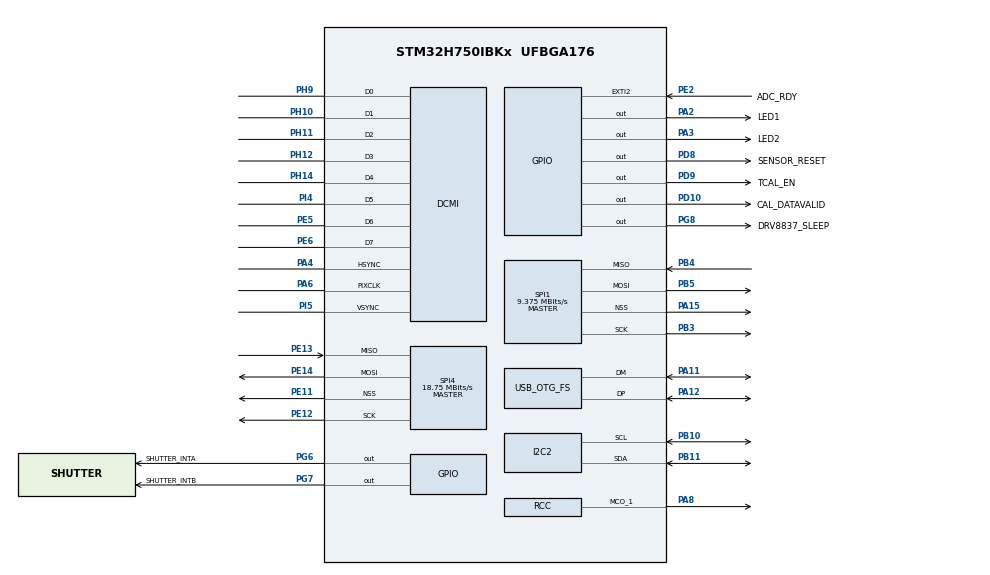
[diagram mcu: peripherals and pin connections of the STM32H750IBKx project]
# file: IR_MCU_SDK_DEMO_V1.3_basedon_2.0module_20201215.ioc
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Dma.DCMI.0.Direction=DMA_PERIPH_TO_MEMORY
Dma.DCMI.0.EventEnable=DISABLE
Dma.DCMI.0.FIFOMode=DMA_FIFOMODE_DISABLE
Dma.DCMI.0.Instance=DMA1_Stream0
Dma.DCMI.0.MemDataAlignment=DMA_MDATAALIGN_WORD
Dma.DCMI.0.MemInc=DMA_MINC_ENABLE
Dma.DCMI.0.Mode=DMA_CIRCULAR
Dma.DCMI.0.PeriphDataAlignment=DMA_PDATAALIGN_WORD
Dma.DCMI.0.PeriphInc=DMA_PINC_DISABLE
Dma.DCMI.0.Polarity=HAL_DMAMUX_REQ_GEN_RISING
Dma.DCMI.0.Priority=DMA_PRIORITY_MEDIUM
Dma.DCMI.0.RequestNumber=1
Dma.DCMI.0.SignalID=NONE
Dma.DCMI.0.SyncEnable=DISABLE
Dma.DCMI.0.SyncPolarity=HAL_DMAMUX_SYNC_NO_EVENT
Dma.DCMI.0.SyncRequestNumber=1
Dma.DCMI.0.SyncSignalID=NONE
Dma.MEMTOMEM.1.Direction=DMA_MEMORY_TO_MEMORY
Dma.MEMTOMEM.1.EventEnable=DISABLE
Dma.MEMTOMEM.1.FIFOMode=DMA_FIFOMODE_ENABLE
Dma.MEMTOMEM.1.FIFOThreshold=DMA_FIFO_THRESHOLD_FULL
Dma.MEMTOMEM.1.Instance=DMA1_Stream1
Dma.MEMTOMEM.1.MemBurst=DMA_MBURST_SINGLE
Dma.MEMTOMEM.1.MemDataAlignment=DMA_MDATAALIGN_WORD
Dma.MEMTOMEM.1.MemInc=DMA_MINC_ENABLE
Dma.MEMTOMEM.1.Mode=DMA_NORMAL
Dma.MEMTOMEM.1.PeriphBurst=DMA_PBURST_SINGLE
Dma.MEMTOMEM.1.PeriphDataAlignment=DMA_PDATAALIGN_WORD
Dma.MEMTOMEM.1.PeriphInc=DMA_PINC_ENABLE
Dma.MEMTOMEM.1.Polarity=HAL_DMAMUX_REQ_GEN_RISING
Dma.MEMTOMEM.1.Priority=DMA_PRIORITY_LOW
Dma.MEMTOMEM.1.RequestNumber=1
Dma.MEMTOMEM.1.SignalID=NONE
Dma.MEMTOMEM.1.SyncEnable=DISABLE
Dma.MEMTOMEM.1.SyncPolarity=HAL_DMAMUX_SYNC_NO_EVENT
Dma.MEMTOMEM.1.SyncRequestNumber=1
Dma.MEMTOMEM.1.SyncSignalID=NONE
Dma.Request0=DCMI
Dma.Request1=MEMTOMEM
FREERTOS.Tasks01=defaultTask,0,128,StartDefaultTask,As weak,NULL,Dynamic,NULL,NULL;irCameraTask,2,128,StartIRCameraTask,As weak,NULL,Dynamic,NULL,NULL
FREERTOS.configUSE_NEWLIB_REENTRANT=1
I2C2.Timing=0x00909FCE
Mcu.Family=STM32H7
Mcu.Name=STM32H750IBKx
Mcu.Package=UFBGA176
NVIC.DCMI_IRQn=true\:5\:0\:false\:false\:true\:true\:true\:true\:true
NVIC.DMA1_Stream0_IRQn=true\:5\:0\:false\:false\:true\:true\:false\:true\:true
NVIC.EXTI2_IRQn=true\:5\:0\:false\:false\:true\:true\:true\:true\:true
NVIC.OTG_FS_IRQn=true\:5\:0\:false\:false\:true\:true\:true\:true\:true
NVIC.PriorityGroup=NVIC_PRIORITYGROUP_4
NVIC.TIM1_UP_IRQn=true\:15\:0\:false\:false\:true\:false\:false\:true\:true
NVIC.TimeBase=TIM1_UP_IRQn
NVIC.TimeBaseIP=TIM1
PA11.Mode=Device_Only
PA11.Signal=USB_OTG_FS_DM
PA12.Mode=Device_Only
PA12.Signal=USB_OTG_FS_DP
PA15\ (JTDI).Mode=NSS_Signal_Hard_Output
PA15\ (JTDI).Signal=SPI1_NSS
PA2.GPIO_Label=LED1
PA2.Signal=GPIO_Output
PA3.GPIO_Label=LED2
PA3.Signal=GPIO_Output
PA4.Mode=Slave_8_bits_External_Synchro
PA4.Signal=DCMI_HSYNC
PA6.Mode=Slave_8_bits_External_Synchro
PA6.Signal=DCMI_PIXCLK
PA8.Mode=Clock-out-1
PA8.Signal=RCC_MCO_1
PB10.GPIO_Pu=GPIO_PULLUP
PB10.Mode=I2C
PB10.Signal=I2C2_SCL
PB11.GPIO_Pu=GPIO_PULLUP
PB11.Mode=I2C
PB11.Signal=I2C2_SDA
PB3\ (JTDO/TRACESWO).GPIO_Speed=GPIO_SPEED_FREQ_VERY_HIGH
PB3\ (JTDO/TRACESWO).Mode=Full_Duplex_Master
PB3\ (JTDO/TRACESWO).Signal=SPI1_SCK
PB4\ (NJTRST).GPIO_Speed=GPIO_SPEED_FREQ_VERY_HIGH
PB4\ (NJTRST).Mode=Full_Duplex_Master
PB4\ (NJTRST).Signal=SPI1_MISO
PB5.GPIO_Speed=GPIO_SPEED_FREQ_VERY_HIGH
PB5.Mode=Full_Duplex_Master
PB5.Signal=SPI1_MOSI
PD10.GPIO_Label=CAL_DATAVALID
PD10.Signal=GPIO_Output
PD8.GPIO_Label=SENSOR_RESET
PD8.PinState=GPIO_PIN_RESET
PD8.Signal=GPIO_Output
PD9.GPIO_Label=TCAL_EN
PD9.Signal=GPIO_Output
PE11.Mode=NSS_Signal_Hard_Output
PE11.Signal=SPI4_NSS
PE12.Mode=Full_Duplex_Master
PE12.Signal=SPI4_SCK
PE13.Mode=Full_Duplex_Master
PE13.Signal=SPI4_MISO
PE14.Mode=Full_Duplex_Master
PE14.Signal=SPI4_MOSI
PE2.GPIO_Label=ADC_RDY
PE2.GPIO_ModeDefaultEXTI=GPIO_MODE_IT_FALLING
PE2.Signal=GPXTI2
PE5.Mode=Slave_8_bits_External_Synchro
PE5.Signal=DCMI_D6
PE6.Mode=Slave_8_bits_External_Synchro
PE6.Signal=DCMI_D7
PG6.GPIO_Label=SHUTTER_INTA
PG6.GPIO_Speed=GPIO_SPEED_FREQ_HIGH
PG6.Signal=GPIO_Output
PG7.GPIO_Label=SHUTTER_INTB
PG7.GPIO_Speed=GPIO_SPEED_FREQ_HIGH
PG7.Signal=GPIO_Output
PG8.GPIO_Label=DRV8837_SLEEP
PG8.GPIO_Speed=GPIO_SPEED_FREQ_HIGH
PG8.Signal=GPIO_Output
PH0-OSC_IN\ (PH0).Mode=HSE-External-Oscillator
PH0-OSC_IN\ (PH0).Signal=RCC_OSC_IN
PH1-OSC_OUT\ (PH1).Mode=HSE-External-Oscillator
PH1-OSC_OUT\ (PH1).Signal=RCC_OSC_OUT
PH10.Mode=Slave_8_bits_External_Synchro
PH10.Signal=DCMI_D1
PH11.Mode=Slave_8_bits_External_Synchro
PH11.Signal=DCMI_D2
PH12.Mode=Slave_8_bits_External_Synchro
PH12.Signal=DCMI_D3
PH14.Mode=Slave_8_bits_External_Synchro
PH14.Signal=DCMI_D4
PH9.Mode=Slave_8_bits_External_Synchro
PH9.Signal=DCMI_D0
PI4.Mode=Slave_8_bits_External_Synchro
PI4.Signal=DCMI_D5
PI5.Mode=Slave_8_bits_External_Synchro
PI5.Signal=DCMI_VSYNC
ProjectManager.HeapSize=0x200
ProjectManager.StackSize=0x400
ProjectManager.TargetToolchain=MDK-ARM V5.32
RCC.ADCFreq_Value=32250000
RCC.APB1Freq_Value=37500000
RCC.APB2Freq_Value=37500000
RCC.APB3Freq_Value=75000000
RCC.APB4Freq_Value=37500000
RCC.CortexFreq_Value=75000000
RCC.D2PPRE1=RCC_APB1_DIV2
RCC.D2PPRE2=RCC_APB2_DIV2
RCC.D3PPRE=RCC_APB4_DIV2
RCC.DIVM1=1
RCC.DIVM3=1
RCC.DIVN1=9
RCC.DIVN3=9
RCC.DIVQ3=3
RCC.HCLKFreq_Value=75000000
RCC.HSE_VALUE=16000000
RCC.PLL3FRACN=3072
RCC.PLLFRACN=3072
RCC.PLLSourceVirtual=RCC_PLLSOURCE_HSE
RCC.RCC_MCO1Source=RCC_MCO1SOURCE_HSE
RCC.RCC_MCODiv1=RCC_MCODIV_4
RCC.SYSCLKFreq_VALUE=75000000
RCC.SYSCLKSource=RCC_SYSCLKSOURCE_PLLCLK
RCC.USBCLockSelection=RCC_USBCLKSOURCE_PLL3
RCC.USBFreq_Value=50000000
SPI1.BaudRatePrescaler=SPI_BAUDRATEPRESCALER_8
SPI1.CalculateBaudRate=9.375 MBits/s
SPI1.DataSize=SPI_DATASIZE_8BIT
SPI1.Direction=SPI_DIRECTION_2LINES
SPI1.Mode=SPI_MODE_MASTER
SPI1.NSSPMode=SPI_NSS_PULSE_DISABLE
SPI1.VirtualNSS=VM_NSSHARD
SPI1.VirtualType=VM_MASTER
SPI4.CalculateBaudRate=18.75 MBits/s
SPI4.DataSize=SPI_DATASIZE_8BIT
SPI4.Direction=SPI_DIRECTION_2LINES
SPI4.Mode=SPI_MODE_MASTER
SPI4.VirtualNSS=VM_NSSHARD
SPI4.VirtualType=VM_MASTER
USB_DEVICE.CLASS_NAME_FS=HID
USB_DEVICE.VirtualMode-HID_FS=Hid
USB_DEVICE.VirtualModeFS=Hid_FS
USB_OTG_FS.VirtualMode=Device_Only
VP_FREERTOS_VS_CMSIS_V1.Mode=CMSIS_V1
VP_SYS_VS_tim1.Mode=TIM1
VP_USB_DEVICE_VS_USB_DEVICE_HID_FS.Mode=HID_FS
board=custom

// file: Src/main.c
/* USER CODE BEGIN Header */
/**
  ******************************************************************************
  * @file           : main.c
  * @brief          : Main program body
  ******************************************************************************
  * @attention
  *
  * <h2><center>&copy; Copyright (c) 2019 STMicroelectronics.
  * All rights reserved.</center></h2>
  *
  * This software component is licensed by ST under Ultimate Liberty license
  * SLA0044, the "License"; You may not use this file except in compliance with
  * the License. You may obtain a copy of the License at:
  *                             www.st.com/SLA0044
  *
  ******************************************************************************
  */
/* USER CODE END Header */
#include "main.h"
#include "cmsis_os.h"
#include "usb_device.h"

DCMI_HandleTypeDef hdcmi;
DMA_HandleTypeDef hdma_dcmi;

I2C_HandleTypeDef hi2c2;

SPI_HandleTypeDef hspi1;
SPI_HandleTypeDef hspi4;

DMA_HandleTypeDef hdma_memtomem_dma1_stream1;
osThreadId defaultTaskHandle;
osThreadId irCameraTaskHandle;

void SystemClock_Config(void);
static void MX_GPIO_Init(void);
static void MX_DMA_Init(void);
static void MX_DCMI_Init(void);
static void MX_I2C2_Init(void);
static void MX_SPI1_Init(void);
static void MX_SPI4_Init(void);
void StartDefaultTask(void const * argument);
void StartIRCameraTask(void const * argument);

/* USER CODE BEGIN 0 */
extern void DMA_DMAXferCplt(DMA_HandleTypeDef *hdma);
/* USER CODE END 0 */

int main(void)
{

  /* MCU Configuration--------------------------------------------------------*/

  /* Reset of all peripherals, Initializes the Flash interface and the Systick. */
  HAL_Init();

  /* Configure the system clock */
  SystemClock_Config();

  /* Initialize all configured peripherals */
  MX_GPIO_Init();
  MX_DMA_Init();
  MX_DCMI_Init();
  MX_I2C2_Init();
  MX_SPI1_Init();
  MX_SPI4_Init();

  /* Create the thread(s) */
  /* definition and creation of defaultTask */
  osThreadDef(defaultTask, StartDefaultTask, osPriorityNormal, 0, 128);
  defaultTaskHandle = osThreadCreate(osThread(defaultTask), NULL);

  /* definition and creation of irCameraTask */
  osThreadDef(irCameraTask, StartIRCameraTask, osPriorityHigh, 0, 128);
  irCameraTaskHandle = osThreadCreate(osThread(irCameraTask), NULL);

  /* Start scheduler */
  osKernelStart();

  /* We should never get here as control is now taken by the scheduler */
  /* Infinite loop */
  while (1)
  {

  }
}

void SystemClock_Config(void)
{
  RCC_OscInitTypeDef RCC_OscInitStruct = {0};
  RCC_ClkInitTypeDef RCC_ClkInitStruct = {0};

  /** Supply configuration update enable
  */
  HAL_PWREx_ConfigSupply(PWR_LDO_SUPPLY);

  /** Configure the main internal regulator output voltage
  */
  __HAL_PWR_VOLTAGESCALING_CONFIG(PWR_REGULATOR_VOLTAGE_SCALE3);

  while(!__HAL_PWR_GET_FLAG(PWR_FLAG_VOSRDY)) {}

  /** Initializes the RCC Oscillators according to the specified parameters
  * in the RCC_OscInitTypeDef structure.
  */
  RCC_OscInitStruct.OscillatorType = RCC_OSCILLATORTYPE_HSE;
  RCC_OscInitStruct.HSEState = RCC_HSE_ON;
  RCC_OscInitStruct.PLL.PLLState = RCC_PLL_ON;
  RCC_OscInitStruct.PLL.PLLSource = RCC_PLLSOURCE_HSE;
  RCC_OscInitStruct.PLL.PLLM = 1;
  RCC_OscInitStruct.PLL.PLLN = 9;
  RCC_OscInitStruct.PLL.PLLP = 2;
  RCC_OscInitStruct.PLL.PLLQ = 2;
  RCC_OscInitStruct.PLL.PLLR = 2;
  RCC_OscInitStruct.PLL.PLLRGE = RCC_PLL1VCIRANGE_3;
  RCC_OscInitStruct.PLL.PLLVCOSEL = RCC_PLL1VCOMEDIUM;
  RCC_OscInitStruct.PLL.PLLFRACN = 3072;
  if (HAL_RCC_OscConfig(&RCC_OscInitStruct) != HAL_OK)
  {
    Error_Handler();
  }

  /** Initializes the CPU, AHB and APB buses clocks
  */
  RCC_ClkInitStruct.ClockType = RCC_CLOCKTYPE_HCLK|RCC_CLOCKTYPE_SYSCLK
                              |RCC_CLOCKTYPE_PCLK1|RCC_CLOCKTYPE_PCLK2
                              |RCC_CLOCKTYPE_D3PCLK1|RCC_CLOCKTYPE_D1PCLK1;
  RCC_ClkInitStruct.SYSCLKSource = RCC_SYSCLKSOURCE_PLLCLK;
  RCC_ClkInitStruct.SYSCLKDivider = RCC_SYSCLK_DIV1;
  RCC_ClkInitStruct.AHBCLKDivider = RCC_HCLK_DIV1;
  RCC_ClkInitStruct.APB3CLKDivider = RCC_APB3_DIV1;
  RCC_ClkInitStruct.APB1CLKDivider = RCC_APB1_DIV2;
  RCC_ClkInitStruct.APB2CLKDivider = RCC_APB2_DIV2;
  RCC_ClkInitStruct.APB4CLKDivider = RCC_APB4_DIV2;

  if (HAL_RCC_ClockConfig(&RCC_ClkInitStruct, FLASH_LATENCY_1) != HAL_OK)
  {
    Error_Handler();
  }
  HAL_RCC_MCOConfig(RCC_MCO1, RCC_MCO1SOURCE_HSE, RCC_MCODIV_4);
}

static void MX_DCMI_Init(void)
{

  hdcmi.Instance = DCMI;
  hdcmi.Init.SynchroMode = DCMI_SYNCHRO_HARDWARE;
  hdcmi.Init.PCKPolarity = DCMI_PCKPOLARITY_FALLING;
  hdcmi.Init.VSPolarity = DCMI_VSPOLARITY_LOW;
  hdcmi.Init.HSPolarity = DCMI_HSPOLARITY_LOW;
  hdcmi.Init.CaptureRate = DCMI_CR_ALL_FRAME;
  hdcmi.Init.ExtendedDataMode = DCMI_EXTEND_DATA_8B;
  hdcmi.Init.JPEGMode = DCMI_JPEG_DISABLE;
  hdcmi.Init.ByteSelectMode = DCMI_BSM_ALL;
  hdcmi.Init.ByteSelectStart = DCMI_OEBS_ODD;
  hdcmi.Init.LineSelectMode = DCMI_LSM_ALL;
  hdcmi.Init.LineSelectStart = DCMI_OELS_ODD;
  if (HAL_DCMI_Init(&hdcmi) != HAL_OK)
  {
    Error_Handler();
  }

}

static void MX_I2C2_Init(void)
{

  hi2c2.Instance = I2C2;
  hi2c2.Init.Timing = 0x00909FCE;
  hi2c2.Init.OwnAddress1 = 0;
  hi2c2.Init.AddressingMode = I2C_ADDRESSINGMODE_7BIT;
  hi2c2.Init.DualAddressMode = I2C_DUALADDRESS_DISABLE;
  hi2c2.Init.OwnAddress2 = 0;
  hi2c2.Init.OwnAddress2Masks = I2C_OA2_NOMASK;
  hi2c2.Init.GeneralCallMode = I2C_GENERALCALL_DISABLE;
  hi2c2.Init.NoStretchMode = I2C_NOSTRETCH_DISABLE;
  if (HAL_I2C_Init(&hi2c2) != HAL_OK)
  {
    Error_Handler();
  }

  /** Configure Analogue filter
  */
  if (HAL_I2CEx_ConfigAnalogFilter(&hi2c2, I2C_ANALOGFILTER_ENABLE) != HAL_OK)
  {
    Error_Handler();
  }

  /** Configure Digital filter
  */
  if (HAL_I2CEx_ConfigDigitalFilter(&hi2c2, 0) != HAL_OK)
  {
    Error_Handler();
  }

}

static void MX_SPI1_Init(void)
{

  /* SPI1 parameter configuration*/
  hspi1.Instance = SPI1;
  hspi1.Init.Mode = SPI_MODE_MASTER;
  hspi1.Init.Direction = SPI_DIRECTION_2LINES;
  hspi1.Init.DataSize = SPI_DATASIZE_8BIT;
  hspi1.Init.CLKPolarity = SPI_POLARITY_LOW;
  hspi1.Init.CLKPhase = SPI_PHASE_1EDGE;
  hspi1.Init.NSS = SPI_NSS_HARD_OUTPUT;
  hspi1.Init.BaudRatePrescaler = SPI_BAUDRATEPRESCALER_8;
  hspi1.Init.FirstBit = SPI_FIRSTBIT_MSB;
  hspi1.Init.TIMode = SPI_TIMODE_DISABLE;
  hspi1.Init.CRCCalculation = SPI_CRCCALCULATION_DISABLE;
  hspi1.Init.CRCPolynomial = 0x0;
  hspi1.Init.NSSPMode = SPI_NSS_PULSE_DISABLE;
  hspi1.Init.NSSPolarity = SPI_NSS_POLARITY_LOW;
  hspi1.Init.FifoThreshold = SPI_FIFO_THRESHOLD_01DATA;
  hspi1.Init.TxCRCInitializationPattern = SPI_CRC_INITIALIZATION_ALL_ZERO_PATTERN;
  hspi1.Init.RxCRCInitializationPattern = SPI_CRC_INITIALIZATION_ALL_ZERO_PATTERN;
  hspi1.Init.MasterSSIdleness = SPI_MASTER_SS_IDLENESS_00CYCLE;
  hspi1.Init.MasterInterDataIdleness = SPI_MASTER_INTERDATA_IDLENESS_00CYCLE;
  hspi1.Init.MasterReceiverAutoSusp = SPI_MASTER_RX_AUTOSUSP_DISABLE;
  hspi1.Init.MasterKeepIOState = SPI_MASTER_KEEP_IO_STATE_DISABLE;
  hspi1.Init.IOSwap = SPI_IO_SWAP_DISABLE;
  if (HAL_SPI_Init(&hspi1) != HAL_OK)
  {
    Error_Handler();
  }

}

static void MX_SPI4_Init(void)
{

  /* SPI4 parameter configuration*/
  hspi4.Instance = SPI4;
  hspi4.Init.Mode = SPI_MODE_MASTER;
  hspi4.Init.Direction = SPI_DIRECTION_2LINES;
  hspi4.Init.DataSize = SPI_DATASIZE_8BIT;
  hspi4.Init.CLKPolarity = SPI_POLARITY_LOW;
  hspi4.Init.CLKPhase = SPI_PHASE_1EDGE;
  hspi4.Init.NSS = SPI_NSS_HARD_OUTPUT;
  hspi4.Init.BaudRatePrescaler = SPI_BAUDRATEPRESCALER_2;
  hspi4.Init.FirstBit = SPI_FIRSTBIT_MSB;
  hspi4.Init.TIMode = SPI_TIMODE_DISABLE;
  hspi4.Init.CRCCalculation = SPI_CRCCALCULATION_DISABLE;
  hspi4.Init.CRCPolynomial = 0x0;
  hspi4.Init.NSSPMode = SPI_NSS_PULSE_ENABLE;
  hspi4.Init.NSSPolarity = SPI_NSS_POLARITY_LOW;
  hspi4.Init.FifoThreshold = SPI_FIFO_THRESHOLD_01DATA;
  hspi4.Init.TxCRCInitializationPattern = SPI_CRC_INITIALIZATION_ALL_ZERO_PATTERN;
  hspi4.Init.RxCRCInitializationPattern = SPI_CRC_INITIALIZATION_ALL_ZERO_PATTERN;
  hspi4.Init.MasterSSIdleness = SPI_MASTER_SS_IDLENESS_00CYCLE;
  hspi4.Init.MasterInterDataIdleness = SPI_MASTER_INTERDATA_IDLENESS_00CYCLE;
  hspi4.Init.MasterReceiverAutoSusp = SPI_MASTER_RX_AUTOSUSP_DISABLE;
  hspi4.Init.MasterKeepIOState = SPI_MASTER_KEEP_IO_STATE_DISABLE;
  hspi4.Init.IOSwap = SPI_IO_SWAP_DISABLE;
  if (HAL_SPI_Init(&hspi4) != HAL_OK)
  {
    Error_Handler();
  }

}

static void MX_DMA_Init(void)
{

  /* DMA controller clock enable */
  __HAL_RCC_DMA1_CLK_ENABLE();

  /* Configure DMA request hdma_memtomem_dma1_stream1 on DMA1_Stream1 */
  hdma_memtomem_dma1_stream1.Instance = DMA1_Stream1;
  hdma_memtomem_dma1_stream1.Init.Request = DMA_REQUEST_MEM2MEM;
  hdma_memtomem_dma1_stream1.Init.Direction = DMA_MEMORY_TO_MEMORY;
  hdma_memtomem_dma1_stream1.Init.PeriphInc = DMA_PINC_ENABLE;
  hdma_memtomem_dma1_stream1.Init.MemInc = DMA_MINC_ENABLE;
  hdma_memtomem_dma1_stream1.Init.PeriphDataAlignment = DMA_PDATAALIGN_WORD;
  hdma_memtomem_dma1_stream1.Init.MemDataAlignment = DMA_MDATAALIGN_WORD;
  hdma_memtomem_dma1_stream1.Init.Mode = DMA_NORMAL;
  hdma_memtomem_dma1_stream1.Init.Priority = DMA_PRIORITY_LOW;
  hdma_memtomem_dma1_stream1.Init.FIFOMode = DMA_FIFOMODE_ENABLE;
  hdma_memtomem_dma1_stream1.Init.FIFOThreshold = DMA_FIFO_THRESHOLD_FULL;
  hdma_memtomem_dma1_stream1.Init.MemBurst = DMA_MBURST_SINGLE;
  hdma_memtomem_dma1_stream1.Init.PeriphBurst = DMA_PBURST_SINGLE;
  if (HAL_DMA_Init(&hdma_memtomem_dma1_stream1) != HAL_OK)
  {
    Error_Handler( );
  }

  /* DMA interrupt init */
  /* DMA1_Stream0_IRQn interrupt configuration */
  HAL_NVIC_SetPriority(DMA1_Stream0_IRQn, 5, 0);
  HAL_NVIC_EnableIRQ(DMA1_Stream0_IRQn);

}

static void MX_GPIO_Init(void)
{
  GPIO_InitTypeDef GPIO_InitStruct = {0};

  /* GPIO Ports Clock Enable */
  __HAL_RCC_GPIOE_CLK_ENABLE();
  __HAL_RCC_GPIOB_CLK_ENABLE();
  __HAL_RCC_GPIOA_CLK_ENABLE();
  __HAL_RCC_GPIOI_CLK_ENABLE();
  __HAL_RCC_GPIOH_CLK_ENABLE();
  __HAL_RCC_GPIOG_CLK_ENABLE();
  __HAL_RCC_GPIOD_CLK_ENABLE();

  /*Configure GPIO pin Output Level */
  HAL_GPIO_WritePin(GPIOG, DRV8837_SLEEP_Pin|SHUTTER_INTB_Pin|SHUTTER_INTA_Pin, GPIO_PIN_RESET);

  /*Configure GPIO pin Output Level */
  HAL_GPIO_WritePin(GPIOD, CAL_DATAVALID_Pin|TCAL_EN_Pin|SENSOR_RESET_Pin, GPIO_PIN_RESET);

  /*Configure GPIO pin Output Level */
  HAL_GPIO_WritePin(GPIOA, LED1_Pin|LED2_Pin, GPIO_PIN_RESET);

  /*Configure GPIO pin : ADC_RDY_Pin */
  GPIO_InitStruct.Pin = ADC_RDY_Pin;
  GPIO_InitStruct.Mode = GPIO_MODE_IT_FALLING;
  GPIO_InitStruct.Pull = GPIO_NOPULL;
  HAL_GPIO_Init(ADC_RDY_GPIO_Port, &GPIO_InitStruct);

  /*Configure GPIO pin : PA8 */
  GPIO_InitStruct.Pin = GPIO_PIN_8;
  GPIO_InitStruct.Mode = GPIO_MODE_AF_PP;
  GPIO_InitStruct.Pull = GPIO_NOPULL;
  GPIO_InitStruct.Speed = GPIO_SPEED_FREQ_LOW;
  GPIO_InitStruct.Alternate = GPIO_AF0_MCO;
  HAL_GPIO_Init(GPIOA, &GPIO_InitStruct);

  /*Configure GPIO pins : DRV8837_SLEEP_Pin SHUTTER_INTB_Pin SHUTTER_INTA_Pin */
  GPIO_InitStruct.Pin = DRV8837_SLEEP_Pin|SHUTTER_INTB_Pin|SHUTTER_INTA_Pin;
  GPIO_InitStruct.Mode = GPIO_MODE_OUTPUT_PP;
  GPIO_InitStruct.Pull = GPIO_NOPULL;
  GPIO_InitStruct.Speed = GPIO_SPEED_FREQ_HIGH;
  HAL_GPIO_Init(GPIOG, &GPIO_InitStruct);

  /*Configure GPIO pins : CAL_DATAVALID_Pin TCAL_EN_Pin SENSOR_RESET_Pin */
  GPIO_InitStruct.Pin = CAL_DATAVALID_Pin|TCAL_EN_Pin|SENSOR_RESET_Pin;
  GPIO_InitStruct.Mode = GPIO_MODE_OUTPUT_PP;
  GPIO_InitStruct.Pull = GPIO_NOPULL;
  GPIO_InitStruct.Speed = GPIO_SPEED_FREQ_LOW;
  HAL_GPIO_Init(GPIOD, &GPIO_InitStruct);

  /*Configure GPIO pins : LED1_Pin LED2_Pin */
  GPIO_InitStruct.Pin = LED1_Pin|LED2_Pin;
  GPIO_InitStruct.Mode = GPIO_MODE_OUTPUT_PP;
  GPIO_InitStruct.Pull = GPIO_NOPULL;
  GPIO_InitStruct.Speed = GPIO_SPEED_FREQ_LOW;
  HAL_GPIO_Init(GPIOA, &GPIO_InitStruct);

  /* EXTI interrupt init*/
  HAL_NVIC_SetPriority(EXTI2_IRQn, 5, 0);
  HAL_NVIC_EnableIRQ(EXTI2_IRQn);

}

__weak void StartDefaultTask(void const * argument)
{
  /* init code for USB_DEVICE */
  MX_USB_DEVICE_Init();
  for(;;)
  {
    osDelay(1);
  }
}

__weak void StartIRCameraTask(void const * argument)
{
  for(;;)
  {
    osDelay(1);
  }
}

void HAL_TIM_PeriodElapsedCallback(TIM_HandleTypeDef *htim)
{
  if (htim->Instance == TIM1) {
    HAL_IncTick();
  }
}

void Error_Handler(void)
{
}

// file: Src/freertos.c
/* USER CODE BEGIN Header */
/**
  ******************************************************************************
  * File Name          : freertos.c
  * Description        : Code for freertos applications
  ******************************************************************************
  * @attention
  *
  * <h2><center>&copy; Copyright (c) 2019 STMicroelectronics.
  * All rights reserved.</center></h2>
  *
  * This software component is licensed by ST under Ultimate Liberty license
  * SLA0044, the "License"; You may not use this file except in compliance with
  * the License. You may obtain a copy of the License at:
  *                             www.st.com/SLA0044
  *
  ******************************************************************************
  */
/* USER CODE END Header */

#include "FreeRTOS.h"
#include "task.h"
#include "main.h"

/* GetIdleTaskMemory prototype (linked to static allocation support) */
void vApplicationGetIdleTaskMemory( StaticTask_t **ppxIdleTaskTCBBuffer, StackType_t **ppxIdleTaskStackBuffer, uint32_t *pulIdleTaskStackSize );

/* USER CODE BEGIN GET_IDLE_TASK_MEMORY */
static StaticTask_t xIdleTaskTCBBuffer;
static StackType_t xIdleStack[configMINIMAL_STACK_SIZE];

void vApplicationGetIdleTaskMemory( StaticTask_t **ppxIdleTaskTCBBuffer, StackType_t **ppxIdleTaskStackBuffer, uint32_t *pulIdleTaskStackSize )
{
  *ppxIdleTaskTCBBuffer = &xIdleTaskTCBBuffer;
  *ppxIdleTaskStackBuffer = &xIdleStack[0];
  *pulIdleTaskStackSize = configMINIMAL_STACK_SIZE;
  /* place for user code */
}
/* USER CODE END GET_IDLE_TASK_MEMORY */
